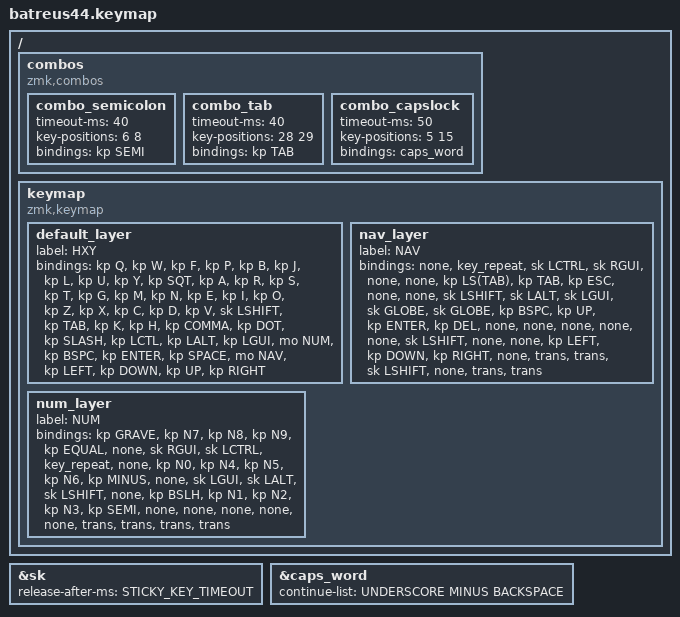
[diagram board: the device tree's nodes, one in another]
/*
 * Copyright (c) 2022 The ZMK Contributors
 *
 * SPDX-License-Identifier: MIT
 */

#define BASE 0
#define NAV 1
#define NUM 2


// Keep sticky keys active for a long time so they effectively do not time out
#define STICKY_KEY_TIMEOUT 60000

// Apple "Globe" key
// https://github.com/zmkfirmware/zmk/issues/947
#define GLOBE CAPSLOCK


#include <behaviors.dtsi>
#include <dt-bindings/zmk/keys.h>
#include <dt-bindings/zmk/bt.h>
#include <dt-bindings/zmk/outputs.h>

&sk {
  release-after-ms = <STICKY_KEY_TIMEOUT>;
};

&caps_word {
  continue-list = <UNDERSCORE MINUS BACKSPACE>;
};

// &kscan0 {
//   debounce-period = <14>;
// };

/ {

//   macros {
//    #include "macros.dtsi"
//   };

    /* KEY POSITIONS
    -- from https://github.com/caksoylar/zmk-config/blob/main/config/combos.dtsi

    ╭────────────────────╮         ╭────────────────────╮
    │  0   1   2   3   4 │         │  5   6   7   8   9 │
    │ 10  11  12  13  14 ╰───╮ ╭───╯ 15  16  17  18  19 │
    │ 20  21  22  23  24  25 │ │ 26  27  28  29  30  31 │
    | 32  33  34  35  36  37 | | 38  39  40  41  42  43 |
    ╰────────────────────────╯ ╰────────────────────────╯
    */
  combos {
      compatible = "zmk,combos";
      combo_semicolon {
          timeout-ms = <40>;
          key-positions = <6 8>;
          bindings = <&kp SEMI>;
      };
      combo_tab {
          timeout-ms = <40>;
          key-positions = <28 29>;
          bindings = <&kp TAB>;
      };
      combo_capslock {
          timeout-ms = <50>;
          key-positions = <5 15>;
          bindings = <&caps_word>;
      };
  };

  keymap {
    compatible = "zmk,keymap";

    default_layer {
      label = "HXY";
      bindings = <
        // ╭─────────────┬─────────────┬─────────────┬─────────────┬─────────────╮                               ╭─────────────┬─────────────┬─────────────┬─────────────┬─────────────╮
             &kp Q         &kp W         &kp F         &kp P         &kp B                                         &kp J         &kp L         &kp U         &kp Y         &kp SQT
        // ├─────────────┼─────────────┼─────────────┼─────────────┼─────────────┤                               ├─────────────┼─────────────┼─────────────┼─────────────┼─────────────┤
             &kp A         &kp R         &kp S         &kp T         &kp G                                         &kp M         &kp N         &kp E         &kp I         &kp O
        // ├─────────────┼─────────────┼─────────────┼─────────────┼─────────────┼─────────────╮   ╭─────────────┼─────────────┼─────────────┼─────────────┼─────────────┼─────────────┤
             &kp Z         &kp X         &kp C         &kp D         &kp V         &sk LSHIFT        &kp TAB       &kp K         &kp H         &kp COMMA     &kp DOT       &kp SLASH
        // ╰─────────────┴─────────────┴─────────────┼─────────────┼─────────────┼─────────────┤   ├─────────────┼─────────────┼─────────────┼─────────────┴─────────────┴─────────────╯
             &kp LCTL      &kp LALT      &kp LGUI      &mo NUM       &kp BSPC      &kp ENTER         &kp SPACE     &mo NAV       &kp LEFT      &kp DOWN      &kp UP        &kp RIGHT
        //                                           ╰─────────────┴─────────────┴─────────────╯   ╰─────────────┴─────────────┴─────────────╯
      >;
    };

    nav_layer {
      label = "NAV";
      bindings = <
        // ╭─────────────┬─────────────┬─────────────┬─────────────┬─────────────╮                               ╭─────────────┬─────────────┬─────────────┬─────────────┬─────────────╮
             &none         &key_repeat   &sk LCTRL     &sk RGUI      &none                                         &none         &kp LS(TAB)   &kp TAB       &kp ESC       &none
        // ├─────────────┼─────────────┼─────────────┼─────────────┼─────────────┤                               ├─────────────┼─────────────┼─────────────┼─────────────┼─────────────┤
             &none         &sk LSHIFT    &sk LALT      &sk LGUI      &sk GLOBE                                     &sk GLOBE     &kp BSPC      &kp UP        &kp ENTER     &kp DEL
        // ├─────────────┼─────────────┼─────────────┼─────────────┼─────────────┼─────────────╮   ╭─────────────┼─────────────┼─────────────┼─────────────┼─────────────┼─────────────┤
             &none         &none         &none         &none         &none         &sk LSHIFT        &none         &none         &kp LEFT      &kp DOWN      &kp RIGHT     &none
        // ╰─────────────┴─────────────┴─────────────┼─────────────┼─────────────┼─────────────┤   ├─────────────┼─────────────┼─────────────┼─────────────┴─────────────┴─────────────╯
                                                       &trans        &trans        &sk LSHIFT        &none         &trans        &trans
        //                                           ╰─────────────┴─────────────┴─────────────╯   ╰─────────────┴─────────────┴─────────────╯
      >;
    };

    num_layer {
      label = "NUM";
      bindings = <
        // ╭─────────────┬─────────────┬─────────────┬─────────────┬─────────────╮                               ╭─────────────┬─────────────┬─────────────┬─────────────┬─────────────╮
             &kp GRAVE     &kp N7        &kp N8        &kp N9        &kp EQUAL                                     &none         &sk RGUI      &sk LCTRL     &key_repeat   &none
        // ├─────────────┼─────────────┼─────────────┼─────────────┼─────────────┤                               ├─────────────┼─────────────┼─────────────┼─────────────┼─────────────┤
             &kp N0        &kp N4        &kp N5        &kp N6        &kp MINUS                                     &none         &sk LGUI      &sk LALT      &sk LSHIFT    &none
        // ├─────────────┼─────────────┼─────────────┼─────────────┼─────────────┼─────────────╮   ╭─────────────┼─────────────┼─────────────┼─────────────┼─────────────┼─────────────┤
             &kp BSLH      &kp N1        &kp N2        &kp N3        &kp SEMI          &none         &none         &none         &none         &none
        // ╰─────────────┴─────────────┴─────────────┼─────────────┼─────────────┼─────────────┤   ├─────────────┼─────────────┼─────────────┼─────────────┴─────────────┴─────────────╯
                                                       &trans        &trans            &trans        &trans
        //                                           ╰─────────────┴─────────────┴─────────────╯   ╰─────────────┴─────────────┴─────────────╯
      >;
    };

  };
};
